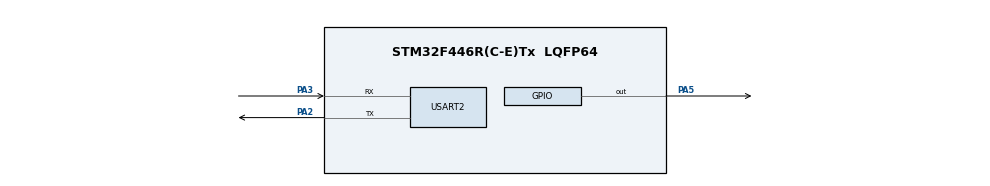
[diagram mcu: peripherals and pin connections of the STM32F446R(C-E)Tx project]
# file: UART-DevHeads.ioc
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Mcu.Family=STM32F4
Mcu.Name=STM32F446R(C-E)Tx
Mcu.Package=LQFP64
NVIC.PriorityGroup=NVIC_PRIORITYGROUP_4
NVIC.USART2_IRQn=true\:0\:0\:false\:false\:true\:true\:true
PA2.Mode=Asynchronous
PA2.Signal=USART2_TX
PA3.Mode=Asynchronous
PA3.Signal=USART2_RX
PA5.Signal=GPIO_Output
ProjectManager.HeapSize=0x200
ProjectManager.StackSize=0x400
ProjectManager.TargetToolchain=STM32CubeIDE
RCC.CortexFreq_Value=16000000
RCC.USBFreq_Value=96000000
RCC.VCOOutputFreq_Value=192000000
USART2.VirtualMode=VM_ASYNC
board=custom

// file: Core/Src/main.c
/* USER CODE BEGIN Header */
/**
 ******************************************************************************
 * @file           : main.c
 * @brief          : Main program body
 ******************************************************************************
 * @attention
 *
 * <h2><center>&copy; Copyright (c) 2024 STMicroelectronics.
 * All rights reserved.</center></h2>
 *
 * This software component is licensed by ST under BSD 3-Clause license,
 * the "License"; You may not use this file except in compliance with the
 * License. You may obtain a copy of the License at:
 *                        opensource.org/licenses/BSD-3-Clause
 *
 ******************************************************************************
 */
/* USER CODE END Header */
#include "main.h"

UART_HandleTypeDef huart2;

/* USER CODE BEGIN PV */
uint8_t tx_buffer[28] = "Welcome to DevHeads! \r\n";
uint8_t rx_indx;
uint8_t rx_data[2];
uint8_t rx_buffer[100];
uint8_t transfer_cplt;

/* USER CODE END PV */

void SystemClock_Config(void);
static void MX_GPIO_Init(void);
static void MX_USART2_UART_Init(void);

int main(void) {

	/* MCU Configuration--------------------------------------------------------*/

	/* Reset of all peripherals, Initializes the Flash interface and the Systick. */
	HAL_Init();

	/* Configure the system clock */
	SystemClock_Config();

	/* Initialize all configured peripherals */
	MX_GPIO_Init();
	MX_USART2_UART_Init();

	/* USER CODE BEGIN 2 */

	HAL_UART_Receive_IT(&huart2, rx_data, 1);

	/* USER CODE END 2 */

	/* Infinite loop */
	while (1) {

		/* USER CODE BEGIN 3 */
//	  HAL_UART_Transmit(&huart2, tx_buffer, sizeof(tx_buffer), HAL_MAX_DELAY);
//	  HAL_Delay(1000);
	}
	/* USER CODE END 3 */
}

void SystemClock_Config(void) {
	RCC_OscInitTypeDef RCC_OscInitStruct = { 0 };
	RCC_ClkInitTypeDef RCC_ClkInitStruct = { 0 };

	/** Configure the main internal regulator output voltage
	 */
	__HAL_RCC_PWR_CLK_ENABLE();
	__HAL_PWR_VOLTAGESCALING_CONFIG(PWR_REGULATOR_VOLTAGE_SCALE3);
	/** Initializes the RCC Oscillators according to the specified parameters
	 * in the RCC_OscInitTypeDef structure.
	 */
	RCC_OscInitStruct.OscillatorType = RCC_OSCILLATORTYPE_HSI;
	RCC_OscInitStruct.HSIState = RCC_HSI_ON;
	RCC_OscInitStruct.HSICalibrationValue = RCC_HSICALIBRATION_DEFAULT;
	RCC_OscInitStruct.PLL.PLLState = RCC_PLL_NONE;
	if (HAL_RCC_OscConfig(&RCC_OscInitStruct) != HAL_OK) {
		Error_Handler();
	}
	/** Initializes the CPU, AHB and APB buses clocks
	 */
	RCC_ClkInitStruct.ClockType = RCC_CLOCKTYPE_HCLK | RCC_CLOCKTYPE_SYSCLK
			| RCC_CLOCKTYPE_PCLK1 | RCC_CLOCKTYPE_PCLK2;
	RCC_ClkInitStruct.SYSCLKSource = RCC_SYSCLKSOURCE_HSI;
	RCC_ClkInitStruct.AHBCLKDivider = RCC_SYSCLK_DIV1;
	RCC_ClkInitStruct.APB1CLKDivider = RCC_HCLK_DIV1;
	RCC_ClkInitStruct.APB2CLKDivider = RCC_HCLK_DIV1;

	if (HAL_RCC_ClockConfig(&RCC_ClkInitStruct, FLASH_LATENCY_0) != HAL_OK) {
		Error_Handler();
	}
}

static void MX_USART2_UART_Init(void) {

	huart2.Instance = USART2;
	huart2.Init.BaudRate = 115200;
	huart2.Init.WordLength = UART_WORDLENGTH_8B;
	huart2.Init.StopBits = UART_STOPBITS_1;
	huart2.Init.Parity = UART_PARITY_NONE;
	huart2.Init.Mode = UART_MODE_TX_RX;
	huart2.Init.HwFlowCtl = UART_HWCONTROL_NONE;
	huart2.Init.OverSampling = UART_OVERSAMPLING_16;
	if (HAL_UART_Init(&huart2) != HAL_OK) {
		Error_Handler();
	}

}

static void MX_GPIO_Init(void) {
	GPIO_InitTypeDef GPIO_InitStruct = { 0 };

	/* GPIO Ports Clock Enable */
	__HAL_RCC_GPIOA_CLK_ENABLE();

	/*Configure GPIO pin Output Level */
	HAL_GPIO_WritePin(GPIOA, GPIO_PIN_5, GPIO_PIN_RESET);

	/*Configure GPIO pin : PA5 */
	GPIO_InitStruct.Pin = GPIO_PIN_5;
	GPIO_InitStruct.Mode = GPIO_MODE_OUTPUT_PP;
	GPIO_InitStruct.Pull = GPIO_NOPULL;
	GPIO_InitStruct.Speed = GPIO_SPEED_FREQ_LOW;
	HAL_GPIO_Init(GPIOA, &GPIO_InitStruct);

}

/* USER CODE BEGIN 4 */

void HAL_UART_RxCpltCallback(UART_HandleTypeDef *huart) {
	/* Prevent unused argument(s) compilation warning */
	UNUSED(huart);
	/* NOTE: This function should not be modified, when the callback is needed,
	 the HAL_UART_RxCpltCallback could be implemented in the user file
	 */

	uint8_t i;
	if (huart->Instance == USART2) {
		if (rx_indx == 0) {
			for (i = 0; i < 100; i++)
				rx_buffer[i] = 0;
			HAL_GPIO_WritePin(GPIOA, GPIO_PIN_5, GPIO_PIN_RESET);
		}

		if (rx_data[0] != 13) {
			rx_buffer[rx_indx++] = rx_data[0];
		} else {
			rx_indx = 0;
			transfer_cplt = 1;
			HAL_UART_Transmit(&huart2, "\n\r", 2, 100);
			if (!strcmp(rx_buffer, "LED ON")) {
				HAL_GPIO_WritePin(GPIOA, GPIO_PIN_5, GPIO_PIN_SET);
			}
		}

		HAL_UART_Receive_IT(&huart2, rx_data, 1);
		HAL_UART_Transmit(&huart2, rx_data, strlen(rx_data), 100);
	}
}

/* USER CODE END 4 */

void Error_Handler(void) {
	__disable_irq();
	while (1) {
	}
}

/************************ (C) COPYRIGHT STMicroelectronics *****END OF FILE****/
